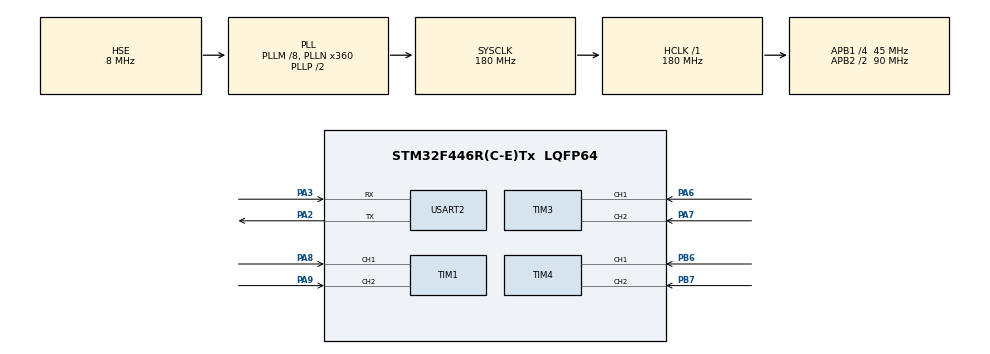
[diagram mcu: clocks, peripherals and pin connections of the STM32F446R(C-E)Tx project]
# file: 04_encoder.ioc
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Dma.Request0=USART2_RX
Dma.Request1=USART2_TX
Dma.USART2_RX.0.Direction=DMA_PERIPH_TO_MEMORY
Dma.USART2_RX.0.FIFOMode=DMA_FIFOMODE_DISABLE
Dma.USART2_RX.0.Instance=DMA1_Stream5
Dma.USART2_RX.0.MemDataAlignment=DMA_MDATAALIGN_BYTE
Dma.USART2_RX.0.MemInc=DMA_MINC_ENABLE
Dma.USART2_RX.0.Mode=DMA_CIRCULAR
Dma.USART2_RX.0.PeriphDataAlignment=DMA_PDATAALIGN_BYTE
Dma.USART2_RX.0.PeriphInc=DMA_PINC_DISABLE
Dma.USART2_RX.0.Priority=DMA_PRIORITY_LOW
Dma.USART2_TX.1.Direction=DMA_MEMORY_TO_PERIPH
Dma.USART2_TX.1.FIFOMode=DMA_FIFOMODE_DISABLE
Dma.USART2_TX.1.Instance=DMA1_Stream6
Dma.USART2_TX.1.MemDataAlignment=DMA_MDATAALIGN_BYTE
Dma.USART2_TX.1.MemInc=DMA_MINC_ENABLE
Dma.USART2_TX.1.Mode=DMA_NORMAL
Dma.USART2_TX.1.PeriphDataAlignment=DMA_PDATAALIGN_BYTE
Dma.USART2_TX.1.PeriphInc=DMA_PINC_DISABLE
Dma.USART2_TX.1.Priority=DMA_PRIORITY_LOW
Mcu.Family=STM32F4
Mcu.Name=STM32F446R(C-E)Tx
Mcu.Package=LQFP64
NVIC.DMA1_Stream5_IRQn=true\:0\:0\:false\:false\:true\:false\:true\:true
NVIC.DMA1_Stream6_IRQn=true\:0\:0\:false\:false\:true\:false\:true\:true
NVIC.PriorityGroup=NVIC_PRIORITYGROUP_0
PA2.Mode=Asynchronous
PA2.Signal=USART2_TX
PA3.Mode=Asynchronous
PA3.Signal=USART2_RX
PA6.Signal=S_TIM3_CH1
PA7.Signal=S_TIM3_CH2
PA8.Signal=S_TIM1_CH1
PA9.Signal=S_TIM1_CH2
PB6.Signal=S_TIM4_CH1
PB7.Signal=S_TIM4_CH2
PH0-OSC_IN.Mode=HSE-External-Clock-Source
PH0-OSC_IN.Signal=RCC_OSC_IN
PH1-OSC_OUT.Mode=HSE-External-Clock-Source
PH1-OSC_OUT.Signal=RCC_OSC_OUT
ProjectManager.HeapSize=0x200
ProjectManager.StackSize=0x400
ProjectManager.TargetToolchain=CMake
RCC.48MHZClocksFreq_Value=84000000
RCC.AHBFreq_Value=180000000
RCC.APB1CLKDivider=RCC_HCLK_DIV4
RCC.APB1Freq_Value=45000000
RCC.APB1TimFreq_Value=90000000
RCC.APB2CLKDivider=RCC_HCLK_DIV2
RCC.APB2Freq_Value=90000000
RCC.APB2TimFreq_Value=180000000
RCC.CortexFreq_Value=180000000
RCC.FLatency-AdvancedSettings=FLASH_LATENCY_5
RCC.HCLKFreq_Value=180000000
RCC.HSE_VALUE=8000000
RCC.HSI_VALUE=16000000
RCC.PLLM=8
RCC.PLLN=360
RCC.PLLSourceVirtual=RCC_PLLSOURCE_HSE
RCC.SYSCLKFreq_VALUE=180000000
RCC.SYSCLKSource=RCC_SYSCLKSOURCE_PLLCLK
RCC.USBFreq_Value=180000000
RCC.VCOOutputFreq_Value=360000000
SH.S_TIM1_CH1.0=TIM1_CH1,Encoder_Interface
SH.S_TIM1_CH2.0=TIM1_CH2,Encoder_Interface
SH.S_TIM3_CH1.0=TIM3_CH1,Encoder_Interface
SH.S_TIM3_CH2.0=TIM3_CH2,Encoder_Interface
SH.S_TIM4_CH1.0=TIM4_CH1,Encoder_Interface
SH.S_TIM4_CH2.0=TIM4_CH2,Encoder_Interface
TIM1.EncoderMode=TIM_ENCODERMODE_TI12
TIM3.EncoderMode=TIM_ENCODERMODE_TI12
TIM4.EncoderMode=TIM_ENCODERMODE_TI12
USART2.VirtualMode=VM_ASYNC
board=NUCLEO-F446RE

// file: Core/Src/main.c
/* USER CODE BEGIN Header */
/**
  ******************************************************************************
  * @file           : main.c
  * @brief          : Main program body
  ******************************************************************************
  * @attention
  *
  * Copyright (c) 2026 STMicroelectronics.
  * All rights reserved.
  *
  * This software is licensed under terms that can be found in the LICENSE file
  * in the root directory of this software component.
  * If no LICENSE file comes with this software, it is provided AS-IS.
  *
  ******************************************************************************
  */
/* USER CODE END Header */
#include "main.h"

/* USER CODE BEGIN Includes */
#include "string.h"
#include "stdio.h"
/* USER CODE END Includes */

TIM_HandleTypeDef htim1;
TIM_HandleTypeDef htim3;
TIM_HandleTypeDef htim4;

UART_HandleTypeDef huart2;
DMA_HandleTypeDef hdma_usart2_rx;
DMA_HandleTypeDef hdma_usart2_tx;

/* USER CODE BEGIN PV */

// Absolute encoder positions
volatile int32_t encZ1 = 0;
volatile int32_t encZ2 = 0;
volatile int32_t encX  = 0;

// Previous raw timer counts
uint16_t prevZ1 = 0;
uint16_t prevZ2 = 0;
uint16_t prevX  = 0;

// UART print buffer
char uartBuf[64];

/* USER CODE END PV */

void SystemClock_Config(void);
static void MX_GPIO_Init(void);
static void MX_DMA_Init(void);
static void MX_USART2_UART_Init(void);
static void MX_TIM1_Init(void);
static void MX_TIM3_Init(void);
static void MX_TIM4_Init(void);

int main(void)
{

  /* MCU Configuration--------------------------------------------------------*/

  /* Reset of all peripherals, Initializes the Flash interface and the Systick. */
  HAL_Init();

  /* Configure the system clock */
  SystemClock_Config();

  /* Initialize all configured peripherals */
  MX_GPIO_Init();
  MX_DMA_Init();
  MX_USART2_UART_Init();
  MX_TIM1_Init();
  MX_TIM3_Init();
  MX_TIM4_Init();
  /* USER CODE BEGIN 2 */

  HAL_TIM_Encoder_Start(&htim1, TIM_CHANNEL_ALL);
  HAL_TIM_Encoder_Start(&htim3, TIM_CHANNEL_ALL);
  HAL_TIM_Encoder_Start(&htim4, TIM_CHANNEL_ALL);

  /* USER CODE END 2 */

  /* Infinite loop */
  while (1)
  {

    // Read deltas
    uint16_t curZ1 = (uint16_t)__HAL_TIM_GET_COUNTER(&htim1);
    uint16_t curZ2 = (uint16_t)__HAL_TIM_GET_COUNTER(&htim3);
    uint16_t curX  = (uint16_t)__HAL_TIM_GET_COUNTER(&htim4);

    encZ1 += (int16_t)(curZ1 - prevZ1);
    encZ2 += (int16_t)(curZ2 - prevZ2);
    encX  += (int16_t)(curX  - prevX);

    prevZ1 = curZ1;
    prevZ2 = curZ2;
    prevX  = curX;

    // Print every 500ms
    int len = snprintf(uartBuf, sizeof(uartBuf),
        "Z1:%ld  Z2:%ld  X:%ld\r\n", encZ1, encZ2, encX);
    HAL_UART_Transmit(&huart2, (uint8_t*)uartBuf, len, 100);

    HAL_Delay(500);

  }
}

void SystemClock_Config(void)
{
  RCC_OscInitTypeDef RCC_OscInitStruct = {0};
  RCC_ClkInitTypeDef RCC_ClkInitStruct = {0};

  /** Configure the main internal regulator output voltage
  */
  __HAL_RCC_PWR_CLK_ENABLE();
  __HAL_PWR_VOLTAGESCALING_CONFIG(PWR_REGULATOR_VOLTAGE_SCALE1);

  /** Initializes the RCC Oscillators according to the specified parameters
  * in the RCC_OscInitTypeDef structure.
  */
  RCC_OscInitStruct.OscillatorType = RCC_OSCILLATORTYPE_HSE;
  RCC_OscInitStruct.HSEState = RCC_HSE_BYPASS;
  RCC_OscInitStruct.PLL.PLLState = RCC_PLL_ON;
  RCC_OscInitStruct.PLL.PLLSource = RCC_PLLSOURCE_HSE;
  RCC_OscInitStruct.PLL.PLLM = 8;
  RCC_OscInitStruct.PLL.PLLN = 360;
  RCC_OscInitStruct.PLL.PLLP = RCC_PLLP_DIV2;
  RCC_OscInitStruct.PLL.PLLQ = 2;
  RCC_OscInitStruct.PLL.PLLR = 2;
  if (HAL_RCC_OscConfig(&RCC_OscInitStruct) != HAL_OK)
  {
    Error_Handler();
  }

  /** Activate the Over-Drive mode
  */
  if (HAL_PWREx_EnableOverDrive() != HAL_OK)
  {
    Error_Handler();
  }

  /** Initializes the CPU, AHB and APB buses clocks
  */
  RCC_ClkInitStruct.ClockType = RCC_CLOCKTYPE_HCLK|RCC_CLOCKTYPE_SYSCLK
                              |RCC_CLOCKTYPE_PCLK1|RCC_CLOCKTYPE_PCLK2;
  RCC_ClkInitStruct.SYSCLKSource = RCC_SYSCLKSOURCE_PLLCLK;
  RCC_ClkInitStruct.AHBCLKDivider = RCC_SYSCLK_DIV1;
  RCC_ClkInitStruct.APB1CLKDivider = RCC_HCLK_DIV4;
  RCC_ClkInitStruct.APB2CLKDivider = RCC_HCLK_DIV2;

  if (HAL_RCC_ClockConfig(&RCC_ClkInitStruct, FLASH_LATENCY_5) != HAL_OK)
  {
    Error_Handler();
  }
}

static void MX_TIM1_Init(void)
{

  TIM_Encoder_InitTypeDef sConfig = {0};
  TIM_MasterConfigTypeDef sMasterConfig = {0};

  htim1.Instance = TIM1;
  htim1.Init.Prescaler = 0;
  htim1.Init.CounterMode = TIM_COUNTERMODE_UP;
  htim1.Init.Period = 65535;
  htim1.Init.ClockDivision = TIM_CLOCKDIVISION_DIV1;
  htim1.Init.RepetitionCounter = 0;
  htim1.Init.AutoReloadPreload = TIM_AUTORELOAD_PRELOAD_DISABLE;
  sConfig.EncoderMode = TIM_ENCODERMODE_TI12;
  sConfig.IC1Polarity = TIM_ICPOLARITY_RISING;
  sConfig.IC1Selection = TIM_ICSELECTION_DIRECTTI;
  sConfig.IC1Prescaler = TIM_ICPSC_DIV1;
  sConfig.IC1Filter = 0;
  sConfig.IC2Polarity = TIM_ICPOLARITY_RISING;
  sConfig.IC2Selection = TIM_ICSELECTION_DIRECTTI;
  sConfig.IC2Prescaler = TIM_ICPSC_DIV1;
  sConfig.IC2Filter = 0;
  if (HAL_TIM_Encoder_Init(&htim1, &sConfig) != HAL_OK)
  {
    Error_Handler();
  }
  sMasterConfig.MasterOutputTrigger = TIM_TRGO_RESET;
  sMasterConfig.MasterSlaveMode = TIM_MASTERSLAVEMODE_DISABLE;
  if (HAL_TIMEx_MasterConfigSynchronization(&htim1, &sMasterConfig) != HAL_OK)
  {
    Error_Handler();
  }

}

static void MX_TIM3_Init(void)
{

  TIM_Encoder_InitTypeDef sConfig = {0};
  TIM_MasterConfigTypeDef sMasterConfig = {0};

  htim3.Instance = TIM3;
  htim3.Init.Prescaler = 0;
  htim3.Init.CounterMode = TIM_COUNTERMODE_UP;
  htim3.Init.Period = 65535;
  htim3.Init.ClockDivision = TIM_CLOCKDIVISION_DIV1;
  htim3.Init.AutoReloadPreload = TIM_AUTORELOAD_PRELOAD_DISABLE;
  sConfig.EncoderMode = TIM_ENCODERMODE_TI12;
  sConfig.IC1Polarity = TIM_ICPOLARITY_RISING;
  sConfig.IC1Selection = TIM_ICSELECTION_DIRECTTI;
  sConfig.IC1Prescaler = TIM_ICPSC_DIV1;
  sConfig.IC1Filter = 0;
  sConfig.IC2Polarity = TIM_ICPOLARITY_RISING;
  sConfig.IC2Selection = TIM_ICSELECTION_DIRECTTI;
  sConfig.IC2Prescaler = TIM_ICPSC_DIV1;
  sConfig.IC2Filter = 0;
  if (HAL_TIM_Encoder_Init(&htim3, &sConfig) != HAL_OK)
  {
    Error_Handler();
  }
  sMasterConfig.MasterOutputTrigger = TIM_TRGO_RESET;
  sMasterConfig.MasterSlaveMode = TIM_MASTERSLAVEMODE_DISABLE;
  if (HAL_TIMEx_MasterConfigSynchronization(&htim3, &sMasterConfig) != HAL_OK)
  {
    Error_Handler();
  }

}

static void MX_TIM4_Init(void)
{

  TIM_Encoder_InitTypeDef sConfig = {0};
  TIM_MasterConfigTypeDef sMasterConfig = {0};

  htim4.Instance = TIM4;
  htim4.Init.Prescaler = 0;
  htim4.Init.CounterMode = TIM_COUNTERMODE_UP;
  htim4.Init.Period = 65535;
  htim4.Init.ClockDivision = TIM_CLOCKDIVISION_DIV1;
  htim4.Init.AutoReloadPreload = TIM_AUTORELOAD_PRELOAD_DISABLE;
  sConfig.EncoderMode = TIM_ENCODERMODE_TI12;
  sConfig.IC1Polarity = TIM_ICPOLARITY_RISING;
  sConfig.IC1Selection = TIM_ICSELECTION_DIRECTTI;
  sConfig.IC1Prescaler = TIM_ICPSC_DIV1;
  sConfig.IC1Filter = 0;
  sConfig.IC2Polarity = TIM_ICPOLARITY_RISING;
  sConfig.IC2Selection = TIM_ICSELECTION_DIRECTTI;
  sConfig.IC2Prescaler = TIM_ICPSC_DIV1;
  sConfig.IC2Filter = 0;
  if (HAL_TIM_Encoder_Init(&htim4, &sConfig) != HAL_OK)
  {
    Error_Handler();
  }
  sMasterConfig.MasterOutputTrigger = TIM_TRGO_RESET;
  sMasterConfig.MasterSlaveMode = TIM_MASTERSLAVEMODE_DISABLE;
  if (HAL_TIMEx_MasterConfigSynchronization(&htim4, &sMasterConfig) != HAL_OK)
  {
    Error_Handler();
  }

}

static void MX_USART2_UART_Init(void)
{

  huart2.Instance = USART2;
  huart2.Init.BaudRate = 115200;
  huart2.Init.WordLength = UART_WORDLENGTH_8B;
  huart2.Init.StopBits = UART_STOPBITS_1;
  huart2.Init.Parity = UART_PARITY_NONE;
  huart2.Init.Mode = UART_MODE_TX_RX;
  huart2.Init.HwFlowCtl = UART_HWCONTROL_NONE;
  huart2.Init.OverSampling = UART_OVERSAMPLING_16;
  if (HAL_UART_Init(&huart2) != HAL_OK)
  {
    Error_Handler();
  }

}

static void MX_DMA_Init(void)
{

  /* DMA controller clock enable */
  __HAL_RCC_DMA1_CLK_ENABLE();

  /* DMA interrupt init */
  /* DMA1_Stream5_IRQn interrupt configuration */
  HAL_NVIC_SetPriority(DMA1_Stream5_IRQn, 0, 0);
  HAL_NVIC_EnableIRQ(DMA1_Stream5_IRQn);
  /* DMA1_Stream6_IRQn interrupt configuration */
  HAL_NVIC_SetPriority(DMA1_Stream6_IRQn, 0, 0);
  HAL_NVIC_EnableIRQ(DMA1_Stream6_IRQn);

}

static void MX_GPIO_Init(void)
{

  /* GPIO Ports Clock Enable */
  __HAL_RCC_GPIOH_CLK_ENABLE();
  __HAL_RCC_GPIOA_CLK_ENABLE();
  __HAL_RCC_GPIOB_CLK_ENABLE();

}

void Error_Handler(void)
{
  __disable_irq();
  while (1)
  {
  }
}
